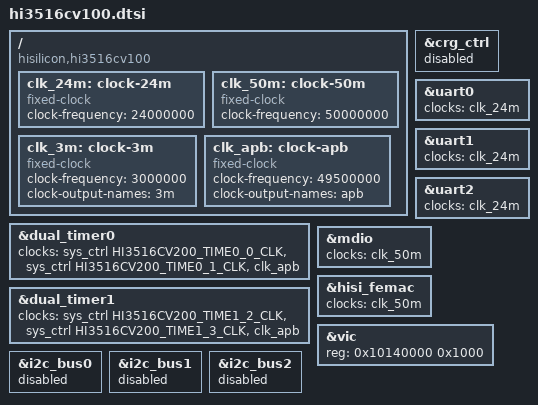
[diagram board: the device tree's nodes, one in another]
// SPDX-License-Identifier: GPL-2.0-or-later
/*
 * HiSilicon Hi3516CV100 SoC family DT (V1 generation, ARM926EJ-S / ARMv5TE).
 *
 * Hi3516CV100 is the parent of Hi3516CV200 — same SoC architecture with
 * a near-identical MMIO map. The only relevant difference for boot is
 * the VIC base (0x10140000 vs cv200's 0x100d0000); CRG, sysctrl, UARTs,
 * SP804 timers, PL022 SPI, FEMAC, FMC, pinmux all sit at identical
 * addresses across the two families. Re-use cv200's full DT scaffold
 * via #include and override the cv100-specific differences below.
 *
 * Sibling SoCs that re-use this dtsi (die-identical per qemu-hisilicon
 * machine model decoding): Hi3518AV100, Hi3518CV100, Hi3518EV100.
 */

#include "hi3516cv200.dtsi"

/ {
	compatible = "hisilicon,hi3516cv100";

	/*
	 * Fixed clocks for what the consumers below need until the V1 CRG has
	 * a driver (see &crg_ctrl). The 3 MHz and APB clocks carry the names
	 * that the SP804 count clock selects of the system controller, which
	 * the Hi3516C V200 clock driver registers for this chip too, take as
	 * their parents.
	 */
	clk_24m: clock-24m {
		compatible = "fixed-clock";
		#clock-cells = <0>;
		clock-frequency = <24000000>;
	};

	clk_50m: clock-50m {
		compatible = "fixed-clock";
		#clock-cells = <0>;
		clock-frequency = <50000000>;
	};

	clk_3m: clock-3m {
		compatible = "fixed-clock";
		#clock-cells = <0>;
		clock-frequency = <3000000>;
		clock-output-names = "3m";
	};

	/* a stand-in rate: the V1 APB clock is a divider of the PLL setting */
	clk_apb: clock-apb {
		compatible = "fixed-clock";
		#clock-cells = <0>;
		clock-frequency = <49500000>;
		clock-output-names = "apb";
	};
};

/*
 * The V1 CRG register map is not the V2 one that hi3516cv200.dtsi describes
 * (no CPU and bus select, no UART select, other SFC and MMC selects, the
 * Ethernet clock and reset bits at 0xcc instead of 0xec), so the Hi3516C V200 clock driver must not
 * gate, select or reset V1 registers by their V2 meaning. It matches the
 * inherited compatible, so the node is disabled: no CRG clock provider and
 * no reset controller exist on this chip until it has a driver of its own,
 * and its consumers get the clocks that they had before that driver was
 * rebuilt from fixed clocks (the UART at 24 MHz and the Ethernet at 50 MHz)
 * or none (the SPI, FMC and I2C nodes). The system controller stays: the
 * SP804 count clock selects in SC_CTRL have the same bits on V1, and the
 * driver reads them back.
 */
&crg_ctrl {
	status = "disabled";
};

&dual_timer0 {
	clocks = <&sys_ctrl HI3516CV200_TIME0_0_CLK>,
		 <&sys_ctrl HI3516CV200_TIME0_1_CLK>,
		 <&clk_apb>;
};

&dual_timer1 {
	clocks = <&sys_ctrl HI3516CV200_TIME1_2_CLK>,
		 <&sys_ctrl HI3516CV200_TIME1_3_CLK>,
		 <&clk_apb>;
};

&uart0 {
	clocks = <&clk_24m>;
};

&uart1 {
	clocks = <&clk_24m>;
};

&uart2 {
	clocks = <&clk_24m>;
};

&mdio {
	clocks = <&clk_50m>;
};

/* there is no reset controller; the reset is optional for the driver */
&hisi_femac {
	clocks = <&clk_50m>;
	/delete-property/ resets;
	/delete-property/ reset-names;
};

/*
 * VIC moves on cv100 — overriding both the unit-address and reg property
 * is straightforward via label-based references. The interrupt-controller
 * type (pl190-vic) and cell layout are unchanged.
 */
&vic {
	reg = <0x10140000 0x1000>;
};

/*
 * cv100 has one I2C controller and uses the older register-poll
 * "hisi-i2c-v1" hardware (not driver-compatible with cv200's HiBVT
 * variant). Boot does not need it — the openhisilicon hi_i2c.ko
 * userspace driver claims the same MMIO directly. Leave all i2c
 * bus nodes disabled.
 */
&i2c_bus0 { status = "disabled"; };
&i2c_bus1 { status = "disabled"; };
&i2c_bus2 { status = "disabled"; };
